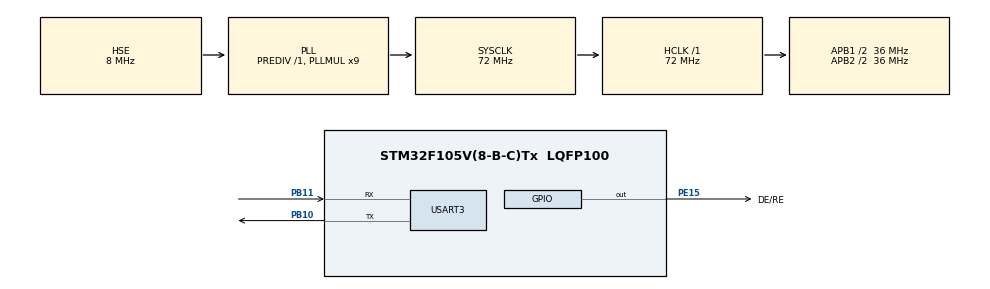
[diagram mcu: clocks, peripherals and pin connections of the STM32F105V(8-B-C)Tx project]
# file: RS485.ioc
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Mcu.Family=STM32F1
Mcu.Name=STM32F105V(8-B-C)Tx
Mcu.Package=LQFP100
NVIC.PriorityGroup=NVIC_PRIORITYGROUP_4
NVIC.TIM2_IRQn=true\:0\:0\:false\:false\:true\:true\:true\:true
NVIC.USART3_IRQn=true\:0\:0\:false\:false\:true\:true\:true\:true
OSC_IN.Mode=HSE-External-Oscillator
OSC_IN.Signal=RCC_OSC_IN
OSC_OUT.Mode=HSE-External-Oscillator
OSC_OUT.Signal=RCC_OSC_OUT
PA13.Mode=Serial_Wire
PA13.Signal=SYS_JTMS-SWDIO
PA14.Mode=Serial_Wire
PA14.Signal=SYS_JTCK-SWCLK
PB10.Mode=Asynchronous
PB10.Signal=USART3_TX
PB11.Mode=Asynchronous
PB11.Signal=USART3_RX
PE15.GPIO_Label=DE/RE
PE15.Signal=GPIO_Output
ProjectManager.HeapSize=0x200
ProjectManager.StackSize=0x400
ProjectManager.TargetToolchain=MDK-ARM V5.32
RCC.AHBFreq_Value=72000000
RCC.APB1CLKDivider=RCC_HCLK_DIV2
RCC.APB1Freq_Value=36000000
RCC.APB1TimFreq_Value=72000000
RCC.APB2CLKDivider=RCC_HCLK_DIV2
RCC.APB2Freq_Value=36000000
RCC.APB2TimFreq_Value=72000000
RCC.HCLKFreq_Value=72000000
RCC.PLLMUL=RCC_PLL_MUL9
RCC.PLLSourceVirtual=RCC_PLLSOURCE_HSE
RCC.SYSCLKFreq_VALUE=72000000
RCC.SYSCLKSource=RCC_SYSCLKSOURCE_PLLCLK
RCC.USBFreq_Value=48000000
TIM2.Period=100-1
TIM2.Prescaler=7200-1
USART3.VirtualMode=VM_ASYNC
VP_TIM2_VS_ClockSourceINT.Mode=Internal
board=custom

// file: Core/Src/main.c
/* USER CODE BEGIN Header */
/**
  ******************************************************************************
  * @file           : main.c
  * @brief          : Main program body
  ******************************************************************************
  * @attention
  *
  * Copyright (c) 2026 STMicroelectronics.
  * All rights reserved.
  *
  * This software is licensed under terms that can be found in the LICENSE file
  * in the root directory of this software component.
  * If no LICENSE file comes with this software, it is provided AS-IS.
  *
  ******************************************************************************
  */
/* USER CODE END Header */
#include "main.h"
#include "tim.h"
#include "usart.h"
#include "gpio.h"
#include "rs485.h"
#include "bms.h"

/* USER CODE BEGIN PV */
//static uint8_t rs485_data[200];

/* USER CODE END PV */

void SystemClock_Config(void);

int main(void)
{

  /* MCU Configuration--------------------------------------------------------*/

  /* Reset of all peripherals, Initializes the Flash interface and the Systick. */
  HAL_Init();

  /* Configure the system clock */
  SystemClock_Config();

  /* Initialize all configured peripherals */
  MX_GPIO_Init();
  MX_USART3_UART_Init();
  MX_RS485_Init();
  MX_TIM2_Init();
  /* USER CODE BEGIN 2 */
	//初始化
	BMS_SendReadBasicInfo(BMS_NextSequence());//0D 01
	HAL_Delay(500);
	BMS_SendReadBasicInfo(BMS_NextSequence());//0D 01
	HAL_Delay(500);
	BMS_SendReadBasicInfo(BMS_NextSequence());//0D 01
	HAL_Delay(500);
	BMS_SendReadSerialNumber(BMS_NextSequence());//0D 04
	HAL_Delay(500);
	//初次认证
	BMS_SendAuthentication30(BMS_NextSequence());//类型30初始认证
	HAL_Delay(500);
	BMS_SendAuthentication30Session(BMS_NextSequence());//类型30会话认证
	HAL_Delay(500);
	BMS_SendAuthentication31(BMS_NextSequence());	//类型31认证
	HAL_Delay(500);
	BMS_SendAuthentication30Session(BMS_NextSequence());//类型30会话认证
	HAL_Delay(500);
	BMS_SendEnableCharging(BMS_NextSequence());//开启充电MOS
	HAL_Delay(500);
	BMS_SendAuthentication31(BMS_NextSequence());	//类型31认证
	HAL_Delay(500);
	BMS_SendAuthentication30Session(BMS_NextSequence());//类型30会话认证
	HAL_Delay(500);
	BMS_SendAuthentication31(BMS_NextSequence());	//类型31认证
	HAL_Delay(500);

  /* USER CODE END 2 */

  /* Infinite loop */
  while (1)
  {

    /* USER CODE BEGIN 3 */
		//485回显测试
//    size_t received = Rs485_ReadData(rs485_data, sizeof(rs485_data));
//    if (received > 0U)
//    {
//      (void)Rs485_SendData(rs485_data, received);
//    }

		BMS_SendReadSerialNumber(BMS_NextSequence());//0D 04在线检测
		HAL_Delay(500);
		BMS_SendReadRealtimeStatus(BMS_NextSequence());//0D 02实时状态
		HAL_Delay(500);
		BMS_SendEnableCharging(BMS_NextSequence());//0D C0 保持充电状态
		HAL_Delay(500);
		BMS_SendReadCellVoltages(BMS_NextSequence());//0D 03单体电压
		HAL_Delay(500);
		BMS_SendReadHardwareParams(BMS_NextSequence());//0D C4充电参数
		HAL_Delay(500);
		BMS_SendReadExtendedStatus(BMS_NextSequence());//0D DA扩展参数
		HAL_Delay(500);
//		//停止充电
//		BMS_SendChargeStopped(BMS_NextSequence());//0D 12
//		HAL_Delay(500);
  }
  /* USER CODE END 3 */
}

void SystemClock_Config(void)
{
  RCC_OscInitTypeDef RCC_OscInitStruct = {0};
  RCC_ClkInitTypeDef RCC_ClkInitStruct = {0};

  /** Initializes the RCC Oscillators according to the specified parameters
  * in the RCC_OscInitTypeDef structure.
  */
  RCC_OscInitStruct.OscillatorType = RCC_OSCILLATORTYPE_HSE;
  RCC_OscInitStruct.HSEState = RCC_HSE_ON;
  RCC_OscInitStruct.HSEPredivValue = RCC_HSE_PREDIV_DIV1;
  RCC_OscInitStruct.HSIState = RCC_HSI_ON;
  RCC_OscInitStruct.Prediv1Source = RCC_PREDIV1_SOURCE_HSE;
  RCC_OscInitStruct.PLL.PLLState = RCC_PLL_ON;
  RCC_OscInitStruct.PLL.PLLSource = RCC_PLLSOURCE_HSE;
  RCC_OscInitStruct.PLL.PLLMUL = RCC_PLL_MUL9;
  RCC_OscInitStruct.PLL2.PLL2State = RCC_PLL_NONE;
  if (HAL_RCC_OscConfig(&RCC_OscInitStruct) != HAL_OK)
  {
    Error_Handler();
  }

  /** Initializes the CPU, AHB and APB buses clocks
  */
  RCC_ClkInitStruct.ClockType = RCC_CLOCKTYPE_HCLK|RCC_CLOCKTYPE_SYSCLK
                              |RCC_CLOCKTYPE_PCLK1|RCC_CLOCKTYPE_PCLK2;
  RCC_ClkInitStruct.SYSCLKSource = RCC_SYSCLKSOURCE_PLLCLK;
  RCC_ClkInitStruct.AHBCLKDivider = RCC_SYSCLK_DIV1;
  RCC_ClkInitStruct.APB1CLKDivider = RCC_HCLK_DIV2;
  RCC_ClkInitStruct.APB2CLKDivider = RCC_HCLK_DIV2;

  if (HAL_RCC_ClockConfig(&RCC_ClkInitStruct, FLASH_LATENCY_2) != HAL_OK)
  {
    Error_Handler();
  }

  /** Configure the Systick interrupt time
  */
  __HAL_RCC_PLLI2S_ENABLE();
}

void Error_Handler(void)
{
  __disable_irq();
  while (1)
  {
  }
}
